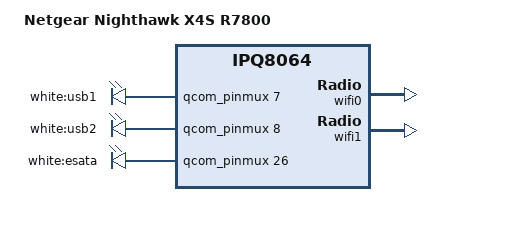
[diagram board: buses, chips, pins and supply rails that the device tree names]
#include "qcom-ipq8065-nighthawk.dtsi"

/ {
	model = "Netgear Nighthawk X4S R7800";
	compatible = "netgear,r7800", "qcom,ipq8065", "qcom,ipq8064";
};

&leds {
	usb1 {
		label = "white:usb1";
		gpios = <&qcom_pinmux 7 GPIO_ACTIVE_HIGH>;
	};

	usb2 {
		label = "white:usb2";
		gpios = <&qcom_pinmux 8 GPIO_ACTIVE_HIGH>;
	};

	esata {
		label = "white:esata";
		gpios = <&qcom_pinmux 26 GPIO_ACTIVE_HIGH>;
	};
};

&partitions {
	partition@1880000 {
		label = "ubi";
		reg = <0x1880000 0x6080000>;
	};

	partition@7900000 {
		label = "reserve";
		reg = <0x7900000 0x0700000>;
		read-only;
	};
};

&wifi0 {
	nvmem-cells = <&macaddr_art_6>, <&precal_art_1000>;
	nvmem-cell-names = "mac-address", "pre-calibration";
	mac-address-increment = <(1)>;
};

&wifi1 {
	nvmem-cells = <&macaddr_art_6>, <&precal_art_5000>;
	nvmem-cell-names = "mac-address", "pre-calibration";
	mac-address-increment = <(2)>;
};
